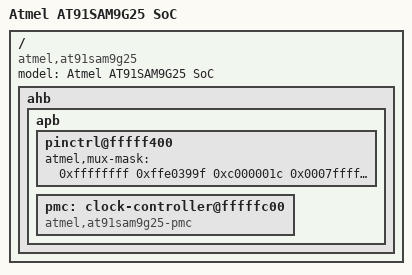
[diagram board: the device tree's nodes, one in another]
#include "at91sam9x5.dtsi"
#include "at91sam9x5_isi.dtsi"
#include "at91sam9x5_usart3.dtsi"
#include "at91sam9x5_macb0.dtsi"
/ {
	model = "Atmel AT91SAM9G25 SoC";
	compatible = "atmel,at91sam9g25", "atmel,at91sam9x5";
	ahb {
		apb {
			pinctrl@fffff400 {
				atmel,mux-mask = <
				       0xffffffff 0xffe0399f 0xc000001c   
				       0x0007ffff 0x00047e3f 0x00000000   
				       0x80000000 0x07c0ffff 0xb83fffff   
				       0x003fffff 0x003f8000 0x00000000   
				      >;
			};
			pmc: clock-controller@fffffc00 {
				compatible = "atmel,at91sam9g25-pmc", "atmel,at91sam9x5-pmc", "syscon";
			};
		};
	};
};
